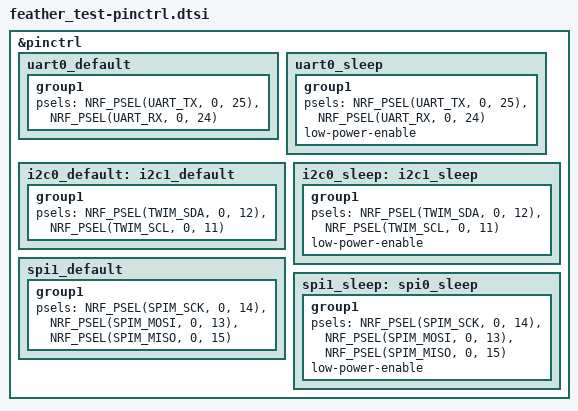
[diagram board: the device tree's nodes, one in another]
/*
 * Copyright (c) 2022 Nordic Semiconductor
 * SPDX-License-Identifier: Apache-2.0
 */

&pinctrl {
	uart0_default: uart0_default {
		group1 {
			psels = <NRF_PSEL(UART_TX, 0, 25)>,
				<NRF_PSEL(UART_RX, 0, 24)>;
		};
	};

	uart0_sleep: uart0_sleep {
		group1 {
			psels = <NRF_PSEL(UART_TX, 0, 25)>,
				<NRF_PSEL(UART_RX, 0, 24)>;
			low-power-enable;
		};
	};

	i2c0_default: i2c1_default {
		group1 {
			psels = <NRF_PSEL(TWIM_SDA, 0, 12)>,
				<NRF_PSEL(TWIM_SCL, 0, 11)>;
		};
	};

	i2c0_sleep: i2c1_sleep {
		group1 {
			psels = <NRF_PSEL(TWIM_SDA, 0, 12)>,
				<NRF_PSEL(TWIM_SCL, 0, 11)>;
			low-power-enable;
		};
	};

	spi1_default: spi1_default {
		group1 {
			psels = <NRF_PSEL(SPIM_SCK, 0, 14)>,
				<NRF_PSEL(SPIM_MOSI, 0, 13)>,
				<NRF_PSEL(SPIM_MISO, 0, 15)>;
		};
	};

	spi1_sleep: spi0_sleep {
		group1 {
			psels = <NRF_PSEL(SPIM_SCK, 0, 14)>,
				<NRF_PSEL(SPIM_MOSI, 0, 13)>,
				<NRF_PSEL(SPIM_MISO, 0, 15)>;
			low-power-enable;
		};
	};

};
